# TOPSS_CTRL register map
Vendor: Texas Instruments
Peripheral module from a debugger description file (folder xwrl64xx).
Registers are 32-bit, read-only, no defined reset value unless marked. A register's access mark holds for its fields unless they carry their own. Offsets are as the file gives them; lines under a group give offsets from that group; [hi:lo] are bit positions; {n}, {i} and the like mark numbered series; 'fields as' and 'values as' point back to an identical list; <NAME> marks a mode.

## TOPSS_CTRL
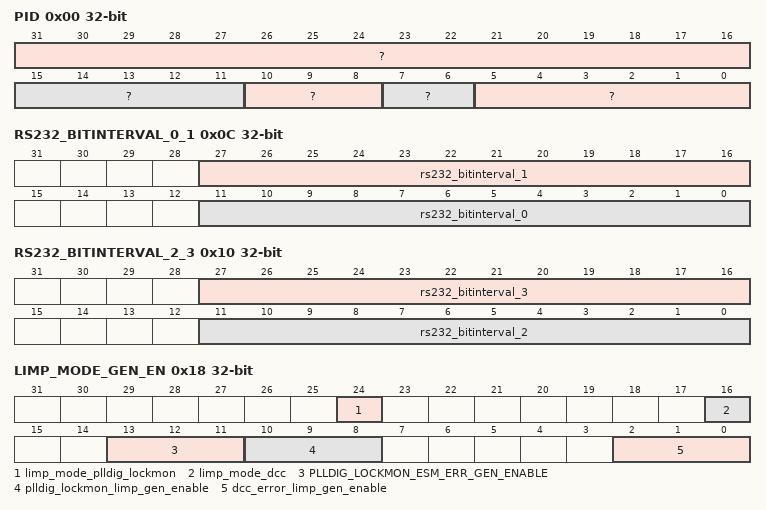
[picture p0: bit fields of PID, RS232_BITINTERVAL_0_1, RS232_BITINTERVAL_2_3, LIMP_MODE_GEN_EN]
0x00 PID
  [31:16] ?, [15:11] ?, [10:8] ?, [7:6] ?, [5:0] ?
0x04 XTAL_FREQ
  [1:0] clkm_xtal_freq — XTAL clock frequency status, 0x0 = 25MHz 0x1 = 40MHz 0x2 = 26MHz 0x3 = 38.4MHz
0x08 SOP_MODE
  [1:0] sop_mode — SOP MODE, 0x0 = Device Management Mode 0x1 = Application Mode 0x2 = Test mode 0x3 = Debug Mode
0x0C RS232_BITINTERVAL_0_1 rw
  [27:16] rs232_bitinterval_1 — BIT Interval value for 40MHz XTAL
  [11:0] rs232_bitinterval_0 — BIT Interval value for 25MHz XTAL
0x10 RS232_BITINTERVAL_2_3 rw
  [27:16] rs232_bitinterval_3 — BIT Interval value for 38.4MHz XTAL
  [11:0] rs232_bitinterval_2 — BIT Interval value for 26MHz XTAL
0x14 DIG_SYNC_SELECT rw
  [1:0] dig_sync_select — Selects dig_sync_in for FRC 2'b00: dig_sync_in 2'b01: mcan_intr 2'b10: lin_intr
0x18 LIMP_MODE_GEN_EN access per field
  [24] limp_mode_plldig_lockmon ro — status reg for limp_mode_plldig_lockmon
  [16] limp_mode_dcc ro — status reg for limp_mode_dcc
  [13:11] PLLDIG_LOCKMON_ESM_ERR_GEN_ENABLE rw — Enable PLLDIG lockmon to generate esm error 3'b000: PLLDIG lockmon will not generate esm error (multibit 000) 3'b111 : PLLDIG lockmon will generate esm error (multibit 111)
  [10:8] plldig_lockmon_limp_gen_enable rw — Enable PLLDIG lockmon to generate Limp mode 3'b000: PLLDIG lockmon will not generate Limp mode (multibit 000) 3'b111 : PLLDIG lockmon will generate Limp mode (multibit 111)
  [2:0] dcc_error_limp_gen_enable rw — Enable EDCC Error to generate Limp mode 3'b000: EDCC Error will not generate Limp mode (multibit 000) 3'b111 : EDCC Error will generate Limp mode (multibit 111)
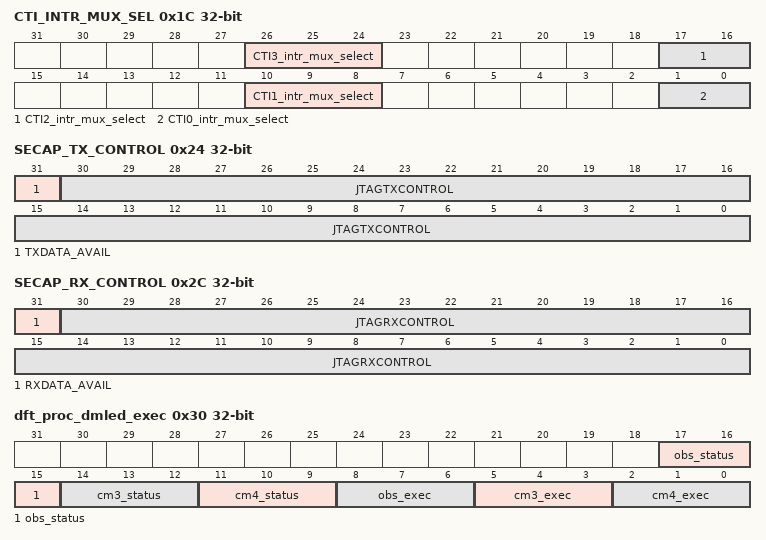
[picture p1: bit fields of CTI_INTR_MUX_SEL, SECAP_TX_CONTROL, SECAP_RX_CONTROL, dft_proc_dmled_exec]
0x1C CTI_INTR_MUX_SEL rw
  [26:24] CTI3_intr_mux_select — CTI3 mux select 3'b000: FRAMETIMER_FRAME_START 3'b001: FRAME_START_OFFSET_INTR_TIME1 3'b010: BURST_START_OFFSET_TIME 3'b011: CHIRPTIMER_BURST_START 3'b100: CHIRPTIMER_BURST_END
  [17:16] CTI2_intr_mux_select — CTI2 mux select 2'b00: CHIRP_AVAIL_IRQ 2'b01: ADC_VALID_START 2'b10: CHIRPTIMER_CHIRP_START 2'b11: CHIRPTIMER_CHIRP_END
  [10:8] CTI1_intr_mux_select — CTI1 mux select 3'b000: app_rti_int_req0 3'b001: app_rti_int_req1 3'b010: tpcc_1_intagg 3'b011: tpcc_2_intagg 3'b100: hwa_loop_int 3'b101: hwa_paramdone_int
  [1:0] CTI0_intr_mux_select — CTI0 mux select 2'b00: ESM_LO_IRQ 2'b01: FEC_INTRundefined 2'b10: FEC_INTRundefined
0x20 SECAP_TX_DATA
  [31:0] JTAGTXDATA — This register is used to pass data to the system security logic. The data is transmit from the external JTAG interface and hence is the Rx path for the SECAP interface.
0x24 SECAP_TX_CONTROL
  [31] TXDATA_AVAIL — Tx Interrupt to indicate avaliablity of TXDATA . 1 - TXDATA available ; 0 - TXDATA not available
  [30:0] JTAGTXCONTROL — This register is provides the handshake for the JTAGTXDATA Register and can also be used to pass control information to the system security logic.
0x28 SECAP_RX_DATA rw
  [31:0] JTAGRXDATA — This register is used to pass data from the system security logic. The data is transmit from the SECAP interface to external JTAG interface and hence is the Tx path for the SECAP interface.
0x2C SECAP_RX_CONTROL access per field
  [31] RXDATA_AVAIL ro — Tx Interrupt to indicate avaliablity of RXDATA . 1 - RXDATA available ; 0 - RXDATA not available
  [30:0] JTAGRXCONTROL rw — This register is provides the handshake for the JTAGRXDATA Register and can also be used to pass control information from the system security logic
0x30 dft_proc_dmled_exec rw
  [17:15] obs_status — dft_proc_dmled_obs_status
  [14:12] cm3_status — dft_proc_dmled_cm3_status
  [11:9] cm4_status — dft_proc_dmled_cm4_status
  [8:6] obs_exec — dft_proc_dmled_obs_exec
  [5:3] cm3_exec — dft_proc_dmled_cm3_exec
  [2:0] cm4_exec — dft_proc_dmled_cm4_exec
0x34 dft_proc_dmled_status rw
0x38 dft_config_reg rw
  [31:0] ctrl — bitundefined: dft_dmled_status_obs_sel
0x3C dft_pbist_st_key rw
  [31:0] reg — dft_pbist_st_key
0x40 dft_pbist_st_rst rw
  [31:0] reg — dft_pbist_st_rst
0x44 TOP_INTMASK rw
  [31:0] set — Mask Interrupt from frame timer 1 : Interrupt is Masked 0 : Interrupt is Unmasked Bit 0 - Mask Interrupts from Frame Timer Bit 31:0 - Reserved
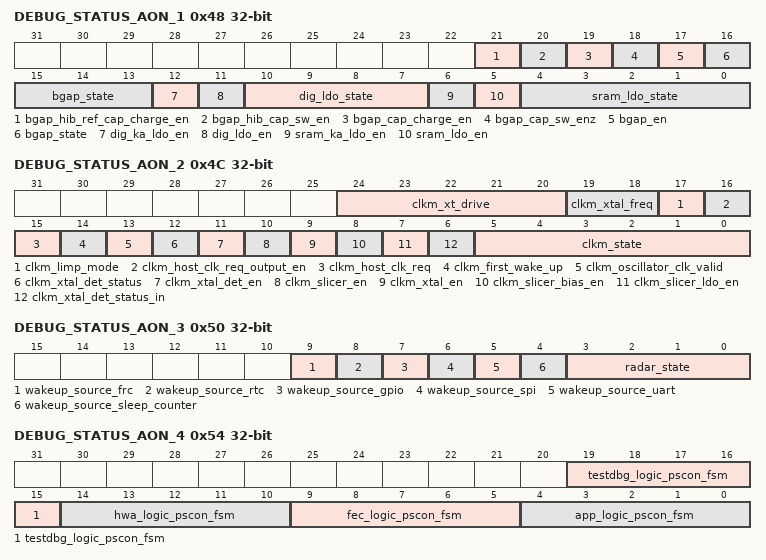
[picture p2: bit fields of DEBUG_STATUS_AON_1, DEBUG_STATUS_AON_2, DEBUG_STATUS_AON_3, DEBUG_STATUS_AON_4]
0x48 DEBUG_STATUS_AON_1
  [21] bgap_hib_ref_cap_charge_en — status reg for bgap_hib_ref_cap_charge_en
  [20] bgap_hib_cap_sw_en — status reg for bgap_hib_cap_sw_en
  [19] bgap_cap_charge_en — status reg for bgap_cap_charge_en
  [18] bgap_cap_sw_enz — status reg for bgap_cap_sw_enz
  [17] bgap_en — status reg for bgap_en
  [16:13] bgap_state — status reg for bgap_state
  [12] dig_ka_ldo_en — status reg for dig_ka_ldo_en
  [11] dig_ldo_en — status reg for dig_ldo_en
  [10:7] dig_ldo_state — status reg for dig_ldo_state
  [6] sram_ka_ldo_en — status reg for sram_ka_ldo_en
  [5] sram_ldo_en — status reg for sram_ldo_en
  [4:0] sram_ldo_state — status reg for sram_ldo_state
0x4C DEBUG_STATUS_AON_2
  [24:20] clkm_xt_drive — status reg for clkm_xt_drive
  [19:18] clkm_xtal_freq — status reg for clkm_xtal_freq
  [17] clkm_limp_mode — status reg for clkm_limp_mode
  [16] clkm_host_clk_req_output_en — status reg for clkm_host_clk_req_output_en
  [15] clkm_host_clk_req — status reg for clkm_host_clk_req
  [14] clkm_first_wake_up — status reg for clkm_first_wake_up
  [13] clkm_oscillator_clk_valid — status reg for clkm_oscillator_clk_valid
  [12] clkm_xtal_det_status — status reg for clkm_xtal_det_status
  [11] clkm_xtal_det_en — status reg for clkm_xtal_det_en
  [10] clkm_slicer_en — status reg for clkm_slicer_en
  [9] clkm_xtal_en — status reg for clkm_xtal_en
  [8] clkm_slicer_bias_en — status reg for clkm_slicer_bias_en
  [7] clkm_slicer_ldo_en — status reg for clkm_slicer_ldo_en
  [6] clkm_xtal_det_status_in — status reg for clkm_xtal_det_status_in
  [5:0] clkm_state — status reg for clkm_state
0x50 DEBUG_STATUS_AON_3
  [9] wakeup_source_frc — status reg for wakeup_source_frc
  [8] wakeup_source_rtc — status reg for wakeup_source_rtc
  [7] wakeup_source_gpio — status reg for wakeup_source_gpio
  [6] wakeup_source_spi — status reg for wakeup_source_spi
  [5] wakeup_source_uart — status reg for wakeup_source_uart
  [4] wakeup_source_sleep_counter — status reg for wakeup_source_sleep_counter
  [3:0] radar_state — status reg for radar_state
0x54 DEBUG_STATUS_AON_4
  [19:15] testdbg_logic_pscon_fsm — status reg for testdbg_logic_pscon_fsm
  [14:10] hwa_logic_pscon_fsm — status reg for hwa_logic_pscon_fsm
  [9:5] fec_logic_pscon_fsm — status reg for fec_logic_pscon_fsm
  [4:0] app_logic_pscon_fsm — status reg for app_logic_pscon_fsm
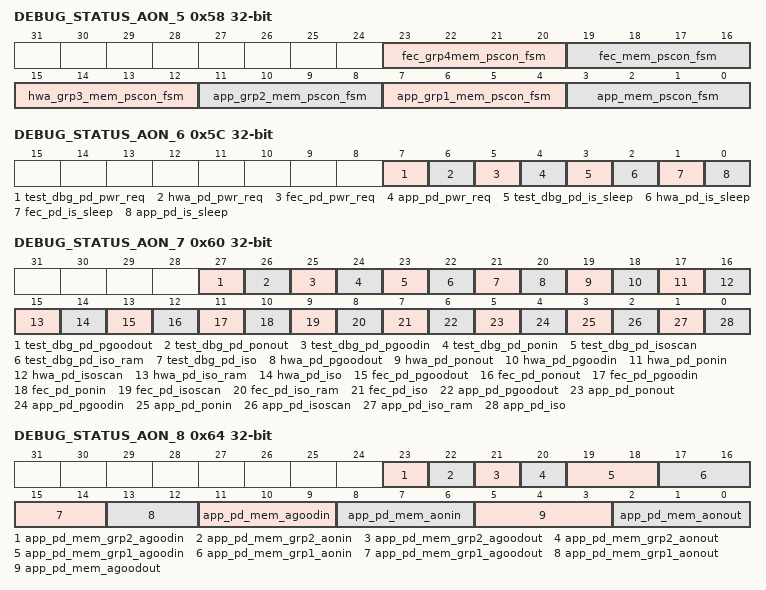
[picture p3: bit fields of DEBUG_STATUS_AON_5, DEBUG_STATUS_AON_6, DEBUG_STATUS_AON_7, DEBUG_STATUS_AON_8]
0x58 DEBUG_STATUS_AON_5
  [23:20] fec_grp4mem_pscon_fsm — status reg for fec_grp4mem_pscon_fsm
  [19:16] fec_mem_pscon_fsm — status reg for fec_mem_pscon_fsm
  [15:12] hwa_grp3_mem_pscon_fsm — status reg for hwa_grp3_mem_pscon_fsm
  [11:8] app_grp2_mem_pscon_fsm — status reg for app_grp2_mem_pscon_fsm
  [7:4] app_grp1_mem_pscon_fsm — status reg for app_grp1_mem_pscon_fsm
  [3:0] app_mem_pscon_fsm — status reg for app_mem_pscon_fsm
0x5C DEBUG_STATUS_AON_6
  [7] test_dbg_pd_pwr_req — status reg for test_dbg_pd_pwr_req
  [6] hwa_pd_pwr_req — status reg for hwa_pd_pwr_req
  [5] fec_pd_pwr_req — status reg for fec_pd_pwr_req
  [4] app_pd_pwr_req — status reg for app_pd_pwr_req
  [3] test_dbg_pd_is_sleep — status reg for test_dbg_pd_is_sleep
  [2] hwa_pd_is_sleep — status reg for hwa_pd_is_sleep
  [1] fec_pd_is_sleep — status reg for fec_pd_is_sleep
  [0] app_pd_is_sleep — status reg for app_pd_is_sleep
0x60 DEBUG_STATUS_AON_7
  [27] test_dbg_pd_pgoodout — status reg for test_dbg_pd_pgoodout
  [26] test_dbg_pd_ponout — status reg for test_dbg_pd_ponout
  [25] test_dbg_pd_pgoodin — status reg for test_dbg_pd_pgoodin
  [24] test_dbg_pd_ponin — status reg for test_dbg_pd_ponin
  [23] test_dbg_pd_isoscan — status reg for test_dbg_pd_isoscan
  [22] test_dbg_pd_iso_ram — status reg for test_dbg_pd_iso_ram
  [21] test_dbg_pd_iso — status reg for test_dbg_pd_iso
  [20] hwa_pd_pgoodout — status reg for hwa_pd_pgoodout
  [19] hwa_pd_ponout — status reg for hwa_pd_ponout
  [18] hwa_pd_pgoodin — status reg for hwa_pd_pgoodin
  [17] hwa_pd_ponin — status reg for hwa_pd_ponin
  [16] hwa_pd_isoscan — status reg for hwa_pd_isoscan
  [15] hwa_pd_iso_ram — status reg for hwa_pd_iso_ram
  [14] hwa_pd_iso — status reg for hwa_pd_iso
  [13] fec_pd_pgoodout — status reg for fec_pd_pgoodout
  [12] fec_pd_ponout — status reg for fec_pd_ponout
  [11] fec_pd_pgoodin — status reg for fec_pd_pgoodin
  [10] fec_pd_ponin — status reg for fec_pd_ponin
  [9] fec_pd_isoscan — status reg for fec_pd_isoscan
  [8] fec_pd_iso_ram — status reg for fec_pd_iso_ram
  [7] fec_pd_iso — status reg for fec_pd_iso
  [6] app_pd_pgoodout — status reg for app_pd_pgoodout
  [5] app_pd_ponout — status reg for app_pd_ponout
  [4] app_pd_pgoodin — status reg for app_pd_pgoodin
  [3] app_pd_ponin — status reg for app_pd_ponin
  [2] app_pd_isoscan — status reg for app_pd_isoscan
  [1] app_pd_iso_ram — status reg for app_pd_iso_ram
  [0] app_pd_iso — status reg for app_pd_iso
0x64 DEBUG_STATUS_AON_8
  [23] app_pd_mem_grp2_agoodin — status reg for app_pd_mem_grp2_agoodin
  [22] app_pd_mem_grp2_aonin — status reg for app_pd_mem_grp2_aonin
  [21] app_pd_mem_grp2_agoodout — status reg for app_pd_mem_grp2_agoodout
  [20] app_pd_mem_grp2_aonout — status reg for app_pd_mem_grp2_aonout
  [19:18] app_pd_mem_grp1_agoodin — status reg for app_pd_mem_grp1_agoodin
  [17:16] app_pd_mem_grp1_aonin — status reg for app_pd_mem_grp1_aonin
  [15:14] app_pd_mem_grp1_agoodout — status reg for app_pd_mem_grp1_agoodout
  [13:12] app_pd_mem_grp1_aonout — status reg for app_pd_mem_grp1_aonout
  [11:9] app_pd_mem_agoodin — status reg for app_pd_mem_agoodin
  [8:6] app_pd_mem_aonin — status reg for app_pd_mem_aonin
  [5:3] app_pd_mem_agoodout — status reg for app_pd_mem_agoodout
  [2:0] app_pd_mem_aonout — status reg for app_pd_mem_aonout
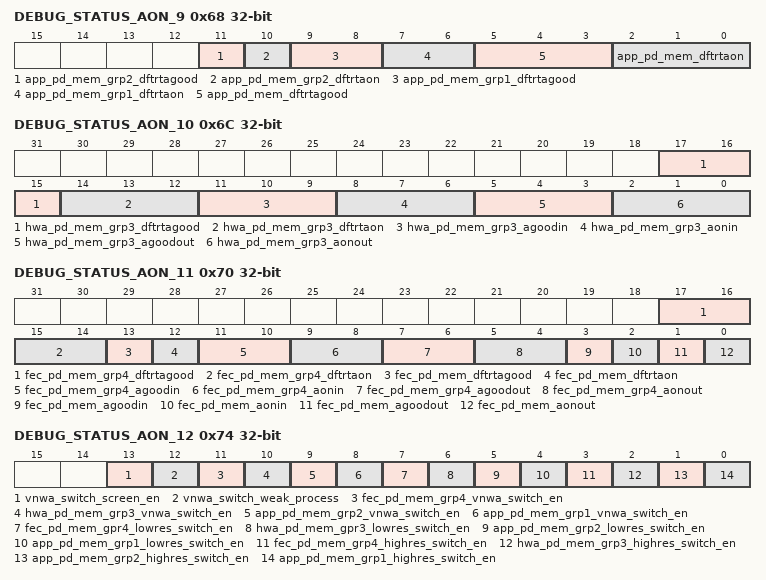
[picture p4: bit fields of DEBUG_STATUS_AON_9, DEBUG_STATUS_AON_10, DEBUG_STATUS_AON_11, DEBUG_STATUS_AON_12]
0x68 DEBUG_STATUS_AON_9
  [11] app_pd_mem_grp2_dftrtagood — status reg for app_pd_mem_grp2_dftrtagood
  [10] app_pd_mem_grp2_dftrtaon — status reg for app_pd_mem_grp2_dftrtaon
  [9:8] app_pd_mem_grp1_dftrtagood — status reg for app_pd_mem_grp1_dftrtagood
  [7:6] app_pd_mem_grp1_dftrtaon — status reg for app_pd_mem_grp1_dftrtaon
  [5:3] app_pd_mem_dftrtagood — status reg for app_pd_mem_dftrtagood
  [2:0] app_pd_mem_dftrtaon — status reg for app_pd_mem_dftrtaon
0x6C DEBUG_STATUS_AON_10
  [17:15] hwa_pd_mem_grp3_dftrtagood — status reg for hwa_pd_mem_grp3_dftrtagood
  [14:12] hwa_pd_mem_grp3_dftrtaon — status reg for hwa_pd_mem_grp3_dftrtaon
  [11:9] hwa_pd_mem_grp3_agoodin — status reg for hwa_pd_mem_grp3_agoodin
  [8:6] hwa_pd_mem_grp3_aonin — status reg for hwa_pd_mem_grp3_aonin
  [5:3] hwa_pd_mem_grp3_agoodout — status reg for hwa_pd_mem_grp3_agoodout
  [2:0] hwa_pd_mem_grp3_aonout — status reg for hwa_pd_mem_grp3_aonout
0x70 DEBUG_STATUS_AON_11
  [17:16] fec_pd_mem_grp4_dftrtagood — status reg for fec_pd_mem_grp4_dftrtagood
  [15:14] fec_pd_mem_grp4_dftrtaon — status reg for fec_pd_mem_grp4_dftrtaon
  [13] fec_pd_mem_dftrtagood — status reg for fec_pd_mem_dftrtagood
  [12] fec_pd_mem_dftrtaon — status reg for fec_pd_mem_dftrtaon
  [11:10] fec_pd_mem_grp4_agoodin — status reg for fec_pd_mem_grp4_agoodin
  [9:8] fec_pd_mem_grp4_aonin — status reg for fec_pd_mem_grp4_aonin
  [7:6] fec_pd_mem_grp4_agoodout — status reg for fec_pd_mem_grp4_agoodout
  [5:4] fec_pd_mem_grp4_aonout — status reg for fec_pd_mem_grp4_aonout
  [3] fec_pd_mem_agoodin — status reg for fec_pd_mem_agoodin
  [2] fec_pd_mem_aonin — status reg for fec_pd_mem_aonin
  [1] fec_pd_mem_agoodout — status reg for fec_pd_mem_agoodout
  [0] fec_pd_mem_aonout — status reg for fec_pd_mem_aonout
0x74 DEBUG_STATUS_AON_12
  [13] vnwa_switch_screen_en — status reg for vnwa_switch_screen_en
  [12] vnwa_switch_weak_process — status reg for vnwa_switch_weak_process
  [11] fec_pd_mem_grp4_vnwa_switch_en — status reg for fec_pd_mem_grp4_vnwa_switch_en
  [10] hwa_pd_mem_grp3_vnwa_switch_en — status reg for hwa_pd_mem_grp3_vnwa_switch_en
  [9] app_pd_mem_grp2_vnwa_switch_en — status reg for app_pd_mem_grp2_vnwa_switch_en
  [8] app_pd_mem_grp1_vnwa_switch_en — status reg for app_pd_mem_grp1_vnwa_switch_en
  [7] fec_pd_mem_gpr4_lowres_switch_en — status reg for fec_pd_mem_gpr4_lowres_switch_en
  [6] hwa_pd_mem_gpr3_lowres_switch_en — status reg for hwa_pd_mem_gpr3_lowres_switch_en
  [5] app_pd_mem_grp2_lowres_switch_en — status reg for app_pd_mem_grp2_lowres_switch_en
  [4] app_pd_mem_grp1_lowres_switch_en — status reg for app_pd_mem_grp1_lowres_switch_en
  [3] fec_pd_mem_grp4_highres_switch_en — status reg for fec_pd_mem_grp4_highres_switch_en
  [2] hwa_pd_mem_grp3_highres_switch_en — status reg for hwa_pd_mem_grp3_highres_switch_en
  [1] app_pd_mem_grp2_highres_switch_en — status reg for app_pd_mem_grp2_highres_switch_en
  [0] app_pd_mem_grp1_highres_switch_en — status reg for app_pd_mem_grp1_highres_switch_en
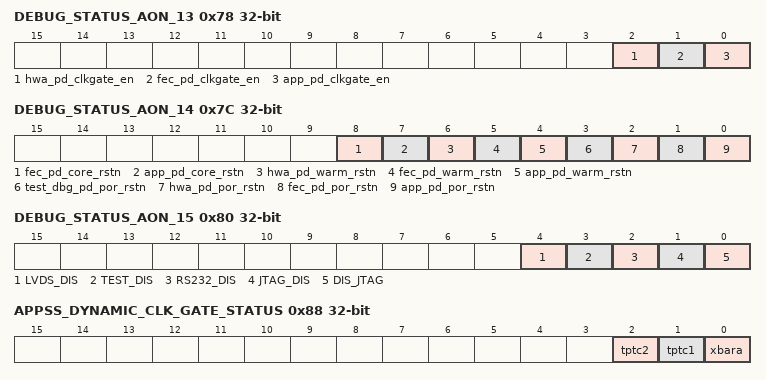
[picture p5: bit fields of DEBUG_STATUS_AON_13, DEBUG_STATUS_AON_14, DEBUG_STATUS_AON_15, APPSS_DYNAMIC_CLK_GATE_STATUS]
0x78 DEBUG_STATUS_AON_13
  [2] hwa_pd_clkgate_en — status reg for hwa_pd_clkgate_en
  [1] fec_pd_clkgate_en — status reg for fec_pd_clkgate_en
  [0] app_pd_clkgate_en — status reg for app_pd_clkgate_en
0x7C DEBUG_STATUS_AON_14
  [8] fec_pd_core_rstn — status reg for fec_pd_core_rstn
  [7] app_pd_core_rstn — status reg for app_pd_core_rstn
  [6] hwa_pd_warm_rstn — status reg for hwa_pd_warm_rstn
  [5] fec_pd_warm_rstn — status reg for fec_pd_warm_rstn
  [4] app_pd_warm_rstn — status reg for app_pd_warm_rstn
  [3] test_dbg_pd_por_rstn — status reg for test_dbg_pd_por_rstn
  [2] hwa_pd_por_rstn — status reg for hwa_pd_por_rstn
  [1] fec_pd_por_rstn — status reg for fec_pd_por_rstn
  [0] app_pd_por_rstn — status reg for app_pd_por_rstn
0x80 DEBUG_STATUS_AON_15
  [4] LVDS_DIS — status reg for LVDS_DIS
  [3] TEST_DIS — status reg for TEST_DIS
  [2] RS232_DIS — status reg for RS232_DIS
  [1] JTAG_DIS — status reg for JTAG_DIS
  [0] DIS_JTAG — status reg for DIS_JTAG
0x84 DEBUG_STATUS_AON_16
  [0] icemelter_powakeemu — status reg for icemelter_powakeemu
0x88 APPSS_DYNAMIC_CLK_GATE_STATUS
  [2] tptc2 — Dynamic Clock gate Status of TPTC2 1 - Clock is Enabled 0 - Clock is Gated.
  [1] tptc1 — Dynamic Clock gate Status of TPTC1 1 - Clock is Enabled 0 - Clock is Gated.
  [0] xbara — Dynamic Clock gate Status of XBARA 1 - Clock is Enabled 0 - Clock is Gated.
0x1008 LOCK0_KICK0 rw — - KICK0 component
  [31:0] ?
0x100C LOCK0_KICK1 rw — - KICK1 component
  [31:0] ?
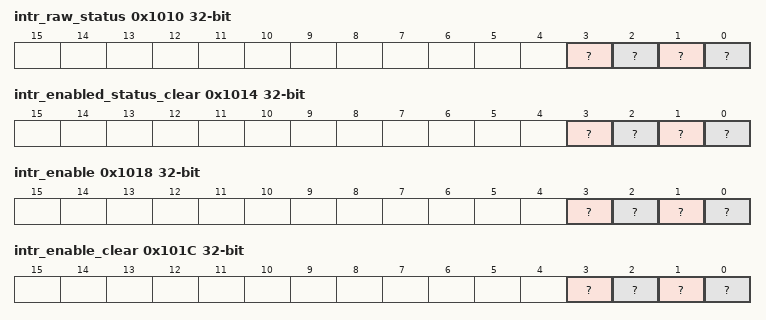
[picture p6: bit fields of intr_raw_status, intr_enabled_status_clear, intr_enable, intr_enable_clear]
0x1010 intr_raw_status rw — Interrupt Raw Status/Set Register
  [3] ? — Proxy0 access violation error. Raw status is read. Write a 1 to set the status. Writing a 0 has no effect.
  [2] ? — Kick access violation error. Raw status is read. Write a 1 to set the status. Writing a 0 has no effect.
  [1] ? — Addressing violation error. Raw status is read. Write a 1 to set the status. Writing a 0 has no effect.
  [0] ? — Protection violation error. Raw status is read. Write a 1 to set the status. Writing a 0 has no effect.
0x1014 intr_enabled_status_clear rw — Interrupt Enabled Status/Clear register
  [3] ? — Proxy0 access violation error. Enabled status is read. Write a 1 to clear the status. Writing a 0 has no effect.
  [2] ? — Kick access violation error. Enabled status is read. Write a 1 to clear the status. Writing a 0 has no effect.
  [1] ? — Addressing violation error. Enabled status is read. Write a 1 to clear the status. Writing a 0 has no effect.
  [0] ? — Protection violation error. Enabled status is read. Write a 1 to clear the status. Writing a 0 has no effect.
0x1018 intr_enable rw — Interrupt Enable register
  [3] ? — Proxy0 access violation error enable. Write a 1 to set the enable. Writing a 0 has no effect.
  [2] ? — Kick access violation error enable. Write a 1 to set the enable. Writing a 0 has no effect.
  [1] ? — Addressing violation error enable. Write a 1 to set the enable. Writing a 0 has no effect.
  [0] ? — Protection violation error enable. Write a 1 to set the enable. Writing a 0 has no effect.
0x101C intr_enable_clear rw — Interrupt Enable Clear register
  [3] ? — Proxy0 access violation error enable clear. Write a 1 to clear the enable. Writing a 0 has no effect.
  [2] ? — Kick access violation error enable clear. Write a 1 to clear the enable. Writing a 0 has no effect.
  [1] ? — Addressing violation error enable clear. Write a 1 to clear the enable. Writing a 0 has no effect.
  [0] ? — Protection violation error enable clear. Write a 1 to clear the enable. Writing a 0 has no effect.
0x1020 eoi rw
  [7:0] ? — EOI vector value. Write this with interrupt distribution value in the chip.
0x1024 fault_address
  [31:0] ? — Fault Address.
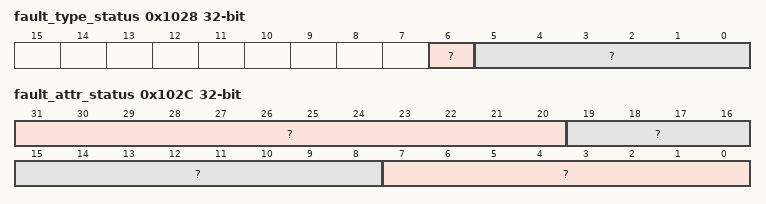
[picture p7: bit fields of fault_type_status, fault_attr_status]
0x1028 fault_type_status
  [6] ? — Non-secure access.
  [5:0] ? — Fault Type 10_0000 = Supervisor read fault - priv = 1 dir = 1 dtype != 1 01_0000 = Supervisor write fault - priv = 1 dir = 0 00_1000 = Supervisor execute fault - priv = 1 dir = 1 dtype = 1 00_0100 = User read fault - priv = 0 dir = 1 dtype = 1 00_0010 = User write fault - priv = 0 dir = 0 00_0001 = User execute fault - priv = 0 dir = 1 dtype = 1 00_0000 = No fault
0x102C fault_attr_status — Fault Attribute Status register
  [31:20] ? — XID.
  [19:8] ? — Route ID.
  [7:0] ? — Privilege ID.
0x1030 fault_clear wo
  [0] ? — Fault clear. Writing a 1 clears the current fault. Writing a 0 has no effect.
